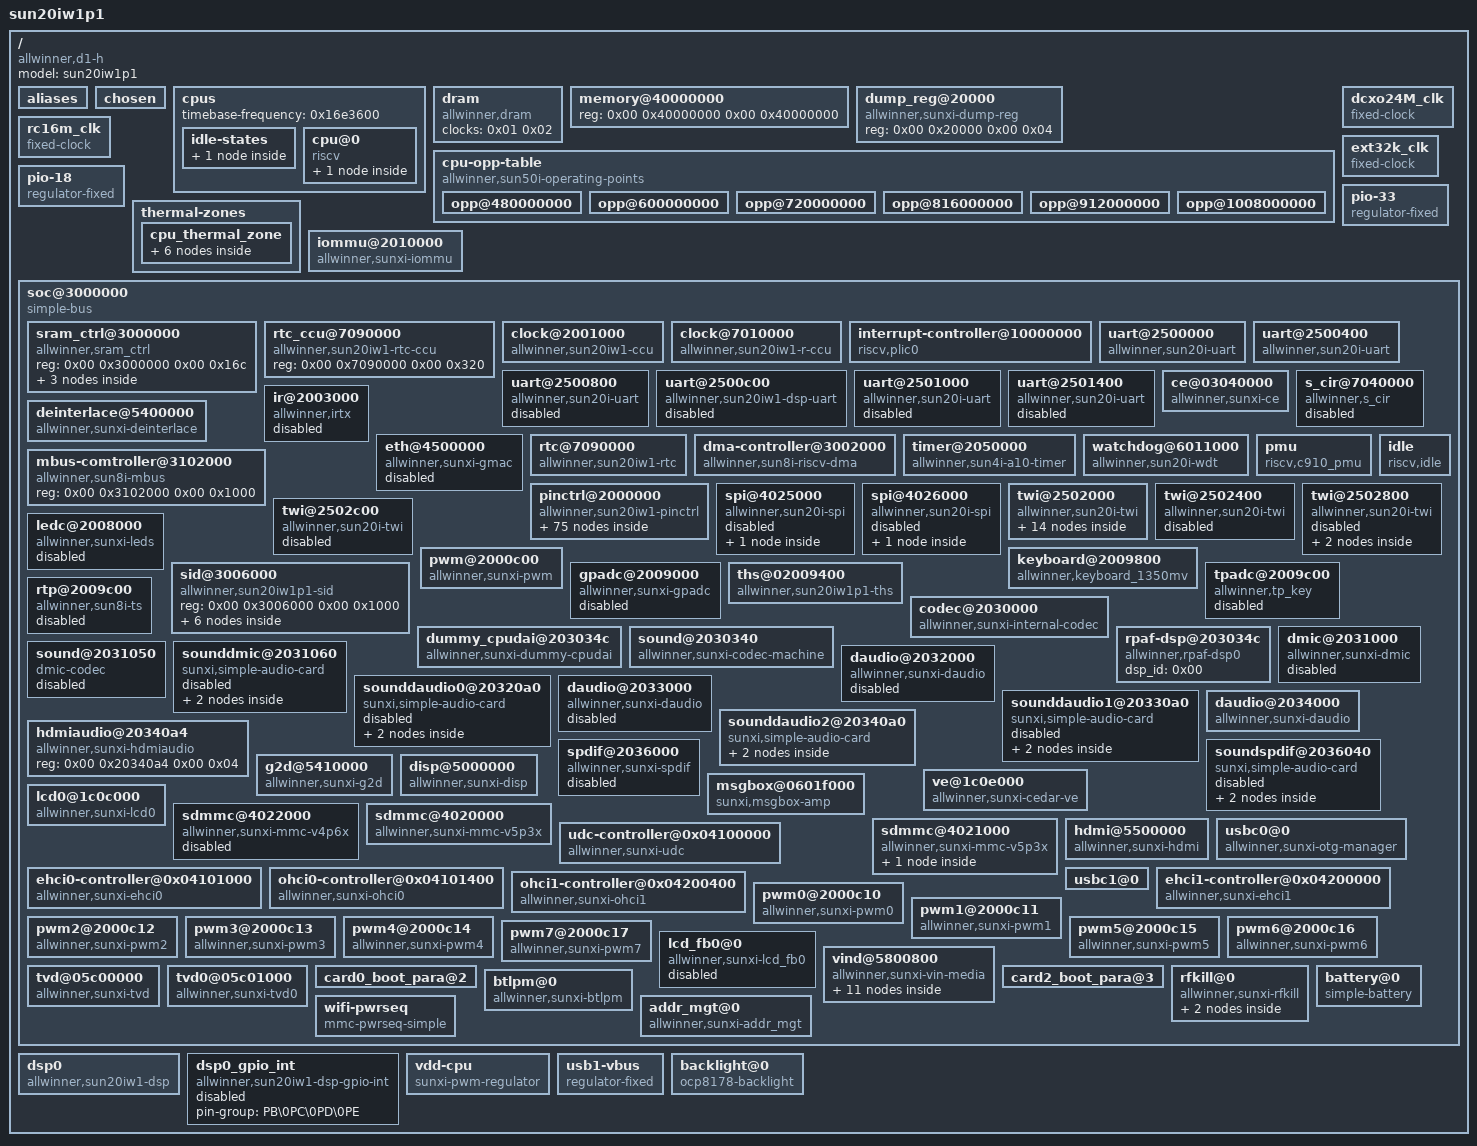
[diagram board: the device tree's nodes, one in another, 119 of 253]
/*
 * This is extracted from the supplied R-01 image's `/boot` partition.
 * TODO: work out what license this is covered by before committing.
 */
/dts-v1/;
 
/memreserve/	0x0000000042000000 0x0000000000100000;
/memreserve/	0x0000000041fc0000 0x0000000000020000;

/ {
	model = "sun20iw1p1";
	compatible = "allwinner,d1-h\0arm,sun20iw1p1\0allwinner,sun20iw1p1";
	#address-cells = <0x02>;
	#size-cells = <0x02>;
 
	aliases {
		serial0 = "/soc@3000000/uart@2500000";
		serial1 = "/soc@3000000/uart@2500400";
		serial2 = "/soc@3000000/uart@2500800";
		serial3 = "/soc@3000000/uart@2500c00";
		serial4 = "/soc@3000000/uart@2501000";
		serial5 = "/soc@3000000/uart@2501400";
		spi0 = "/soc@3000000/spi@4025000";
		spi1 = "/soc@3000000/spi@4026000";
		twi0 = "/soc@3000000/twi@2502000";
		twi1 = "/soc@3000000/twi@2502400";
		twi2 = "/soc@3000000/twi@2502800";
		twi3 = "/soc@3000000/twi@2502c00";
		mmc2 = "/soc@3000000/sdmmc@4022000";
		pwm0 = "/soc@3000000/pwm0@2000c10";
		pwm1 = "/soc@3000000/pwm1@2000c11";
		pwm2 = "/soc@3000000/pwm2@2000c12";
		pwm3 = "/soc@3000000/pwm3@2000c13";
		pwm4 = "/soc@3000000/pwm4@2000c14";
		pwm5 = "/soc@3000000/pwm5@2000c15";
		pwm6 = "/soc@3000000/pwm6@2000c16";
		pwm7 = "/soc@3000000/pwm7@2000c17";
		ir0 = "/soc@3000000/s_cir@7040000";
		ir1 = "/soc@3000000/ir@2003000";
		mmc0 = "/soc@3000000/sdmmc@4020000";
		ve0 = "/soc@3000000/ve@1c0e000";
		tvd = "/soc@3000000/tvd@05c00000";
		tvd0 = "/soc@3000000/tvd0@05c01000";
		dsp0 = "/dsp0";
		dsp0_gpio_int = "/dsp0_gpio_int";
		gmac0 = "/soc@3000000/eth@4500000";
	};
 
	chosen {
		bootargs = "console=ttyS0,115200n8 debug loglevel=7,initcall_debug=1 init=/init earlycon=sbi";
		stdout-path = "serial0:115200n8";
		linux,initrd-start = <0x42000000>;
		linux,initrd-end = <0x43000000>;
	};
 
	cpus {
		#address-cells = <0x01>;
		#size-cells = <0x00>;
		timebase-frequency = <0x16e3600>;
 
		idle-states {
 
			cpu-sleep {
				compatible = "riscv,idle-state";
				local-timer-stop;
				entry-latency-us = <0x3b>;
				exit-latency-us = <0x3b>;
				min-residency-us = <0x1388>;
				phandle = <0x03>;
			};
		};
 
		cpu@0 {
			device_type = "cpu";
			reg = <0x00>;
			status = "okay";
			compatible = "riscv";
			riscv,isa = "rv64imafdcvsu";
			mmu-type = "riscv,sv39";
			clocks = <0x01 0x87>;
			clock-frequency = <0x16e3600>;
			operating-points-v2 = <0x02>;
			cpu-idle-states = <0x03>;
			#cooling-cells = <0x02>;
			cpu-supply = <0x04>;
			phandle = <0x09>;
 
			interrupt-controller {
				#interrupt-cells = <0x01>;
				interrupt-controller;
				compatible = "riscv,cpu-intc";
				phandle = <0x0d>;
			};
		};
	};
 
	dram {
		device_type = "dram";
		compatible = "allwinner,dram";
		clocks = <0x01 0x02>;
		clock-names = "pll_ddr";
	};
 
	memory@40000000 {
		device_type = "memory";
		reg = <0x00 0x40000000 0x00 0x40000000>;
	};
 
	dump_reg@20000 {
		compatible = "allwinner,sunxi-dump-reg";
		reg = <0x00 0x20000 0x00 0x04>;
	};
 
	cpu-opp-table {
		compatible = "allwinner,sun50i-operating-points";
		nvmem-cells = <0x05 0x06>;
		nvmem-cell-names = "speed\0bin";
		opp-shared;
		phandle = <0x02>;
 
		opp@480000000 {
			opp-hz = <0x00 0x1c9c3800>;
			clock-latency-ns = <0x3b9b0>;
			opp-microvolt-a0 = <0xdbba0>;
			opp-microvolt-a1 = <0xdbba0>;
			opp-microvolt-b0 = <0xe7ef0>;
			opp-microvolt-b1 = <0xe7ef0>;
			opp-microvolt-c0 = <0xe7ef0>;
			opp-microvolt-c1 = <0xe7ef0>;
			opp-supported-hw = <0x07>;
		};
 
		opp@600000000 {
			opp-hz = <0x00 0x23c34600>;
			clock-latency-ns = <0x3b9b0>;
			opp-microvolt-b0 = <0xe7ef0>;
			opp-microvolt-c0 = <0xe7ef0>;
			opp-microvolt-c1 = <0xe7ef0>;
			opp-supported-hw = <0x06>;
		};
 
		opp@720000000 {
			opp-hz = <0x00 0x2aea5400>;
			clock-latency-ns = <0x3b9b0>;
			opp-microvolt-a0 = <0xe7ef0>;
			opp-microvolt-a1 = <0xdbba0>;
			opp-microvolt-b0 = <0xe7ef0>;
			opp-microvolt-b1 = <0xe7ef0>;
			opp-microvolt-c0 = <0xe7ef0>;
			opp-microvolt-c1 = <0xe7ef0>;
			opp-supported-hw = <0x07>;
		};
 
		opp@816000000 {
			opp-hz = <0x00 0x30a32c00>;
			clock-latency-ns = <0x3b9b0>;
			opp-microvolt-a0 = <0xf4240>;
			opp-microvolt-a1 = <0xdbba0>;
			opp-microvolt-b1 = <0xe7ef0>;
			opp-supported-hw = <0x01>;
		};
 
		opp@912000000 {
			opp-hz = <0x00 0x365c0400>;
			clock-latency-ns = <0x3b9b0>;
			opp-microvolt-a0 = <0x100590>;
			opp-microvolt-a1 = <0xdbba0>;
			opp-microvolt-b1 = <0xe7ef0>;
			opp-microvolt-c1 = <0xe7ef0>;
			opp-supported-hw = <0x05>;
		};
 
		opp@1008000000 {
			opp-hz = <0x00 0x3c14dc00>;
			clock-latency-ns = <0x3b9b0>;
			opp-microvolt-a0 = <0x10c8e0>;
			opp-microvolt-a1 = <0xe7ef0>;
			opp-microvolt-b1 = <0xe7ef0>;
			opp-microvolt-c1 = <0xe7ef0>;
			opp-supported-hw = <0x05>;
		};
	};
 
	dcxo24M_clk {
		#clock-cells = <0x00>;
		compatible = "fixed-clock";
		clock-frequency = <0x16e3600>;
		clock-output-names = "dcxo24M";
		phandle = <0x0b>;
	};
 
	rc16m_clk {
		#clock-cells = <0x00>;
		compatible = "fixed-clock";
		clock-frequency = <0xf42400>;
		clock-accuracy = <0x11e1a300>;
		clock-output-names = "rc-16m";
	};
 
	ext32k_clk {
		#clock-cells = <0x00>;
		compatible = "fixed-clock";
		clock-frequency = <0x8000>;
		clock-output-names = "ext-32k";
	};
 
	pio-18 {
		compatible = "regulator-fixed";
		regulator-name = "pio-18";
		regulator-min-microvolt = <0x1b7740>;
		regulator-max-microvolt = <0x1b7740>;
		phandle = <0x1e>;
	};
 
	pio-33 {
		compatible = "regulator-fixed";
		regulator-name = "pio-33";
		regulator-min-microvolt = <0x325aa0>;
		regulator-max-microvolt = <0x325aa0>;
		phandle = <0x1f>;
	};
 
	thermal-zones {
 
		cpu_thermal_zone {
			polling-delay-passive = <0x1f4>;
			polling-delay = <0x3e8>;
			thermal-sensors = <0x07 0x00>;
			sustainable-power = <0x4b0>;
 
			trips {
 
				trip-point@0 {
					temperature = <0x11170>;
					type = "passive";
					hysteresis = <0x00>;
				};
 
				trip-point@1 {
					temperature = <0x15f90>;
					type = "passive";
					hysteresis = <0x00>;
					phandle = <0x08>;
				};
 
				cpu_crit@0 {
					temperature = <0x1adb0>;
					type = "critical";
					hysteresis = <0x00>;
				};
			};
 
			cooling-maps {
 
				map0 {
					trip = <0x08>;
					cooling-device = <0x09 0xffffffff 0xffffffff>;
					contribution = <0x400>;
				};
			};
		};
	};
 
	iommu@2010000 {
		compatible = "allwinner,sunxi-iommu";
		reg = <0x00 0x2010000 0x00 0x1000>;
		interrupts-extended = <0x0a 0x50 0x04>;
		interrupt-names = "iommu-irq";
		clocks = <0x01 0x30>;
		clock-names = "iommu";
		#iommu-cells = <0x02>;
		status = "okay";
		phandle = <0x1a>;
	};
 
	soc@3000000 {
		#address-cells = <0x02>;
		#size-cells = <0x02>;
		compatible = "simple-bus";
		ranges;
 
		sram_ctrl@3000000 {
			compatible = "allwinner,sram_ctrl";
			reg = <0x00 0x3000000 0x00 0x16c>;
 
			soc_ver {
				offset = <0x24>;
				mask = <0x07>;
				shift = <0x00>;
				ver_a = <0x18590000>;
				ver_b = <0x18590002>;
				ver_d = <0x18590003>;
			};
 
			soc_id {
				offset = <0x200>;
				mask = <0x01>;
				shift = <0x16>;
			};
 
			soc_bin {
				offset = <0x00>;
				mask = <0x3ff>;
				shift = <0x00>;
			};
		};
 
		rtc_ccu@7090000 {
			compatible = "allwinner,sun20iw1-rtc-ccu";
			device_type = "rtc-ccu";
			reg = <0x00 0x7090000 0x00 0x320>;
			#clock-cells = <0x01>;
			phandle = <0x0c>;
		};
 
		clock@2001000 {
			compatible = "allwinner,sun20iw1-ccu";
			reg = <0x00 0x2001000 0x00 0x1000>;
			clocks = <0x0b 0x0c 0x03 0x0c 0x00>;
			clock-names = "hosc\0losc\0iosc";
			#clock-cells = <0x01>;
			#reset-cells = <0x01>;
			phandle = <0x01>;
		};
 
		clock@7010000 {
			compatible = "allwinner,sun20iw1-r-ccu";
			reg = <0x00 0x7010000 0x00 0x240>;
			clocks = <0x0b 0x0c 0x03 0x0c 0x00 0x01 0x04>;
			clock-names = "hosc\0losc\0iosc\0pll-periph0";
			#clock-cells = <0x01>;
			#reset-cells = <0x01>;
			phandle = <0x15>;
		};
 
		interrupt-controller@10000000 {
			compatible = "riscv,plic0";
			#address-cells = <0x02>;
			#interrupt-cells = <0x02>;
			interrupt-controller;
			reg = <0x00 0x10000000 0x00 0x4000000>;
			interrupts-extended = <0x0d 0xffffffff 0x0d 0x09>;
			reg-names = "control";
			riscv,max-priority = <0x07>;
			riscv,ndev = <0xc8>;
			phandle = <0x0a>;
		};
 
		uart@2500000 {
			compatible = "allwinner,sun20i-uart";
			device_type = "uart0";
			reg = <0x00 0x2500000 0x00 0x400>;
			interrupts-extended = <0x0a 0x12 0x04>;
			clocks = <0x01 0x3f>;
			clock-names = "uart0";
			resets = <0x01 0x12>;
			sunxi,uart-fifosize = <0x40>;
			uart0_port = <0x00>;
			uart0_type = <0x02>;
			status = "okay";
			pinctrl-names = "default\0sleep";
			pinctrl-0 = <0x0e>;
			pinctrl-1 = <0x0f>;
		};
 
		uart@2500400 {
			compatible = "allwinner,sun20i-uart";
			device_type = "uart1";
			reg = <0x00 0x2500400 0x00 0x400>;
			interrupts-extended = <0x0a 0x13 0x04>;
			sunxi,uart-fifosize = <0x100>;
			clocks = <0x01 0x40>;
			clock-names = "uart1";
			resets = <0x01 0x13>;
			uart1_port = <0x01>;
			uart1_type = <0x04>;
			status = "okay";
			pinctrl-names = "default\0sleep";
			pinctrl-0 = <0x10>;
			pinctrl-1 = <0x11>;
		};
 
		uart@2500800 {
			compatible = "allwinner,sun20i-uart";
			device_type = "uart2";
			reg = <0x00 0x2500800 0x00 0x400>;
			interrupts-extended = <0x0a 0x14 0x04>;
			sunxi,uart-fifosize = <0x100>;
			clocks = <0x01 0x41>;
			clock-names = "uart2";
			resets = <0x01 0x14>;
			uart2_port = <0x02>;
			uart2_type = <0x04>;
			status = "disabled";
			pinctrl-names = "default\0sleep";
			pinctrl-0 = <0x12>;
			pinctrl-1 = <0x13>;
		};
 
		uart@2500c00 {
			compatible = "allwinner,sun20iw1-dsp-uart";
			device_type = "uart3";
			reg = <0x00 0x2500c00 0x00 0x400>;
			interrupts-extended = <0x0a 0x15 0x04>;
			sunxi,uart-fifosize = <0x100>;
			clocks = <0x01 0x42>;
			clock-names = "uart3";
			resets = <0x01 0x15>;
			uart3_port = <0x03>;
			uart3_type = <0x04>;
			status = "disabled";
			pinctrl-names = "default\0sleep";
			pinctrl-0 = <0x14>;
			pinctrl-1 = <0x14>;
		};
 
		uart@2501000 {
			compatible = "allwinner,sun20i-uart";
			device_type = "uart4";
			reg = <0x00 0x2501000 0x00 0x400>;
			interrupts-extended = <0x0a 0x16 0x04>;
			sunxi,uart-fifosize = <0x100>;
			clocks = <0x01 0x43>;
			clock-names = "uart4";
			resets = <0x01 0x16>;
			uart4_port = <0x04>;
			uart4_type = <0x02>;
			status = "disabled";
		};
 
		uart@2501400 {
			compatible = "allwinner,sun20i-uart";
			device_type = "uart5";
			reg = <0x00 0x2501400 0x00 0x400>;
			interrupts-extended = <0x0a 0x17 0x04>;
			sunxi,uart-fifosize = <0x100>;
			clocks = <0x01 0x44>;
			clock-names = "uart5";
			resets = <0x01 0x17>;
			uart5_port = <0x05>;
			uart5_type = <0x02>;
			status = "disabled";
		};
 
		ce@03040000 {
			compatible = "allwinner,sunxi-ce";
			device_name = "ce";
			reg = <0x00 0x3040000 0x00 0xa0 0x00 0x3040800 0x00 0xa0>;
			interrupts-extended = <0x0a 0x44 0x01 0x0a 0x45 0x01>;
			clock-frequency = <0x17d78400>;
			clocks = <0x01 0x24 0x01 0x23 0x01 0x34 0x01 0x05>;
			clock-names = "bus_ce\0ce_clk\0mbus_ce\0pll_periph0_2x";
			resets = <0x01 0x04>;
			status = "okay";
		};
 
		s_cir@7040000 {
			compatible = "allwinner,s_cir";
			reg = <0x00 0x7040000 0x00 0x400>;
			interrupts-extended = <0x0a 0xa7 0x04>;
			clocks = <0x15 0x06 0x0b 0x15 0x05>;
			clock-names = "bus\0pclk\0mclk";
			resets = <0x15 0x03>;
			supply = [00];
			supply_vol = [00];
			status = "disabled";
			pinctrl-names = "default\0sleep";
			pinctrl-0 = <0x16>;
			pinctrl-1 = <0x17>;
		};
 
		ir@2003000 {
			compatible = "allwinner,irtx";
			reg = <0x00 0x2003000 0x00 0x400>;
			interrupts-extended = <0x0a 0x23 0x04>;
			clocks = <0x01 0x52 0x0b 0x01 0x51>;
			clock-names = "bus\0pclk\0mclk";
			resets = <0x01 0x21>;
			status = "disabled";
			pinctrl-names = "default\0sleep";
			pinctrl-0 = <0x18>;
			pinctrl-1 = <0x19>;
		};
 
		deinterlace@5400000 {
			compatible = "allwinner,sunxi-deinterlace";
			reg = <0x00 0x5400000 0x00 0xffff>;
			interrupts-extended = <0x0a 0x68 0x04>;
			clocks = <0x01 0x1f 0x01 0x20 0x01 0x05>;
			clock-names = "clk_di\0pll_periph\0clk_bus_di";
			resets = <0x01 0x02>;
			reset-names = "rst_bus_di";
			assigned-clocks = <0x01 0x1f>;
			assigned-clock-parents = <0x01 0x05>;
			assigned-clock-rates = <0x11e1a300>;
			iommus = <0x1a 0x04 0x01>;
			status = "okay";
		};
 
		eth@4500000 {
			compatible = "allwinner,sunxi-gmac";
			reg = <0x00 0x4500000 0x00 0x10000 0x00 0x3000030 0x00 0x04>;
			interrupts-extended = <0x0a 0x3e 0x04>;
			interrupt-names = "gmacirq";
			clocks = <0x01 0x50 0x01 0x4f>;
			clock-names = "gmac\0ephy";
			resets = <0x01 0x20>;
			device_type = "gmac0";
			pinctrl-0 = <0x1b>;
			pinctrl-1 = <0x1c>;
			pinctrl-names = "default\0sleep";
			phy-mode = "rgmii";
			use_ephy25m = <0x01>;
			tx-delay = <0x03>;
			rx-delay = <0x00>;
			phy-rst = <0x1d 0x04 0x10 0x00>;
			gmac-power0;
			gmac-power1;
			gmac-power2;
			status = "disabled";
		};
 
		rtc@7090000 {
			compatible = "allwinner,sun20iw1-rtc";
			device_type = "rtc";
			wakeup-source;
			interrupts-extended = <0x0a 0xa0 0x04>;
			reg = <0x00 0x7090000 0x00 0x320>;
			clocks = <0x15 0x07 0x0c 0x08 0x0c 0x06>;
			clock-names = "r-ahb-rtc\0rtc-spi\0rtc-1k";
			resets = <0x15 0x04>;
			gpr_cur_pos = <0x06>;
			phandle = <0x69>;
		};
 
		dma-controller@3002000 {
			compatible = "allwinner,sun8i-riscv-dma";
			reg = <0x00 0x3002000 0x00 0x1000>;
			interrupts-extended = <0x0a 0x42 0x04>;
			clocks = <0x01 0x27 0x01 0x32>;
			clock-names = "bus\0mbus";
			resets = <0x01 0x06>;
			dma-channels = <0x08>;
			dma-requests = <0x30>;
			#dma-cells = <0x01>;
			status = "okay";
			phandle = <0x20>;
		};
 
		timer@2050000 {
			compatible = "allwinner,sun4i-a10-timer";
			device_type = "soc_timer";
			reg = <0x00 0x2050000 0x00 0xa0>;
			interrupts-extended = <0x0a 0x4b 0x04>;
			clocks = <0x0b>;
			status = "okay";
		};
 
		watchdog@6011000 {
			compatible = "allwinner,sun20i-wdt";
			reg = <0x00 0x6011000 0x00 0x20>;
			interrupts-extended = <0x0a 0x93 0x04>;
		};
 
		mbus-comtroller@3102000 {
			compatible = "allwinner,sun8i-mbus";
			reg = <0x00 0x3102000 0x00 0x1000>;
			#mbus-cells = <0x01>;
		};
 
		pmu {
			compatible = "riscv,c910_pmu";
		};
 
		idle {
			compatible = "riscv,idle";
		};
 
		pinctrl@2000000 {
			compatible = "allwinner,sun20iw1-pinctrl";
			reg = <0x00 0x2000000 0x00 0x500>;
			interrupts-extended = <0x0a 0x55 0x04 0x0a 0x57 0x04 0x0a 0x59 0x04 0x0a 0x5b 0x04 0x0a 0x5d 0x04 0x0a 0x5f 0x04>;
			device_type = "pio";
			clocks = <0x01 0x1a 0x0b 0x0c 0x03>;
			clock-names = "apb\0hosc\0losc";
			gpio-controller;
			#gpio-cells = <0x03>;
			interrupt-controller;
			#interrupt-cells = <0x03>;
			#size-cells = <0x00>;
			vcc-pf-supply = <0x1e>;
			vcc-pfo-supply = <0x1f>;
			phandle = <0x1d>;
 
			test_pins@0 {
				allwinner,pins = "PB0\0PB1";
				allwinner,function = "test";
				allwinner,muxsel = <0x07>;
				allwinner,drive = <0x01>;
				allwinner,pull = <0x01>;
			};
 
			test_pins@1 {
				pins = "PB0\0PB1";
				function = "io_disabled";
				allwinner,muxsel = <0x0f>;
				allwinner,drive = <0x01>;
				allwinner,pull = <0x01>;
			};
 
			gmac@0 {
				pins = "PE0\0PE1\0PE2\0PE3\0PE4\0PE5\0PE6\0PE7\0PE8\0PE9\0PE10\0PE11\0PE12\0PE13\0PE14\0PE15";
				function = "gmac0";
				drive-strength = <0x0a>;
				muxsel = <0x08>;
				phandle = <0x1b>;
			};
 
			gmac@1 {
				pins = "PE0\0PE1\0PE2\0PE3\0PE4\0PE5\0PE6\0PE7\0PE8\0PE9\0PE10\0PE11\0PE12\0PE13\0PE14\0PE15";
				function = "gpio_in";
				drive-strength = <0x0a>;
				phandle = <0x1c>;
			};
 
			ir1@0 {
				pins = "PB0";
				function = "ir";
				drive-strength = <0x0a>;
				bias-pull-up;
				phandle = <0x18>;
			};
 
			csi_mclk0@0 {
				pins = "PE3";
				function = "csi0";
				drive-strength = <0x0a>;
				phandle = <0x62>;
			};
 
			csi_mclk0@1 {
				pins = "PE3";
				function = "gpio_in";
				phandle = <0x63>;
			};
 
			csi0@0 {
				pins = "PE2\0PE0\0PE1\0PE4\0PE5\0PE6\0PE7\0PE8\0PE9\0PE10\0PE11";
				function = "ncsi0";
				drive-strength = <0x0a>;
				phandle = <0x64>;
			};
 
			csi0@1 {
				pins = "PE2\0PE0\0PE1\0PE4\0PE5\0PE6\0PE7\0PE8\0PE9\0PE10\0PE11";
				function = "io_disabled";
				drive-strength = <0x0a>;
				phandle = <0x65>;
			};
 
			lvds0@0 {
				pins = "PD0\0PD1\0PD2\0PD3\0PD4\0PD5\0PD6\0PD7\0PD8\0PD9";
				function = "lvds0";
				drive-strength = <0x1e>;
				bias-disable;
			};
 
			lvds0@1 {
				pins = "PD0\0PD1\0PD2\0PD3\0PD4\0PD5\0PD6\0PD7\0PD8\0PD9";
				function = "io_disabled";
				drive-strength = <0x1e>;
				bias-disable;
			};
 
			rgb24@0 {
				pins = "PB2\0PB3\0PD0\0PD1\0PD2\0PD3\0PD4\0PD5\0PB4\0PB5\0PD6\0PD7\0PD8\0PD9\0PD10\0PD11\0PB6\0PB7\0PD12\0PD13\0PD14\0PD15\0PD16\0PD17\0PD18\0PD19\0PD20\0PD21";
				function = "lcd0";
				drive-strength = <0x1e>;
				bias-disable;
			};
 
			rgb24@1 {
				pins = "PB2\0PB3\0PD0\0PD1\0PD2\0PD3\0PD4\0PD5\0PB4\0PB5\0PD6\0PD7\0PD8\0PD9\0PD10\0PD11\0PB6\0PB7\0PD12\0PD13\0PD14\0PD15\0PD16\0PD17\0PD18\0PD19\0PD20\0PD21";
				function = "io_disabled";
				bias-disable;
			};
 
			rgb18@0 {
				pins = "PD0\0PD1\0PD2\0PD3\0PD4\0PD5\0PD6\0PD7\0PD8\0PD9\0PD10\0PD11\0PD12\0PD13\0PD14\0PD15\0PD16\0PD17\0PD18\0PD19\0PD20\0PD21";
				function = "lcd0";
				drive-strength = <0x1e>;
				bias-disable;
			};
 
			rgb18@1 {
				pins = "PD0\0PD1\0PD2\0PD3\0PD4\0PD5\0PD6\0PD7\0PD8\0PD9\0PD10\0PD11\0PD12\0PD13\0PD14\0PD15\0PD16\0PD17\0PD18\0PD19\0PD20\0PD21";
				function = "io_disabled";
				bias-disable;
			};
 
			dsi2lane@0 {
				pins = "PD0\0PD1\0PD2\0PD3\0PD4\0PD5";
				function = "dsi";
				drive-strength = <0x1e>;
				bias-disable;
			};
 
			dsi2lane@1 {
				pins = "PD0\0PD1\0PD2\0PD3\0PD4\0PD5";
				function = "io_disabled";
				bias-disable;
			};
 
			dsi4lane@0 {
				pins = "PD0\0PD1\0PD2\0PD3\0PD4\0PD5\0PD6\0PD7\0PD8\0PD9";
				function = "dsi";
				drive-strength = <0x1e>;
				bias-disable;
				phandle = <0x4f>;
			};
 
			dsi4lane@1 {
				pins = "PD0\0PD1\0PD2\0PD3\0PD4\0PD5\0PD6\0PD7\0PD8\0PD9";
				function = "io_disabled";
				bias-disable;
				phandle = <0x50>;
			};
 
			sdc0@0 {
				allwinner,pins = "PF0\0PF1\0PF2\0PF3\0PF4\0PF5";
				allwinner,function = "sdc0";
				allwinner,muxsel = <0x02>;
				allwinner,drive = <0x03>;
				allwinner,pull = <0x01>;
				pins = "PF0\0PF1\0PF2\0PF3\0PF4\0PF5";
				function = "sdc0";
				drive-strength = <0x1e>;
				bias-pull-up;
				power-source = <0xce4>;
				phandle = <0x53>;
			};
 
			sdc0@1 {
				pins = "PF0\0PF1\0PF2\0PF3\0PF4\0PF5";
				function = "sdc0";
				drive-strength = <0x1e>;
				bias-pull-up;
				power-source = <0x708>;
				phandle = <0x54>;
			};
 
			sdc0@2 {
				pins = "PF0\0PF1\0PF2\0PF3\0PF4\0PF5";
				function = "gpio_in";
				phandle = <0x55>;
			};
 
			sdc0@3 {
				pins = "PF2\0PF4";
				function = "uart0";
				drive-strength = <0x0a>;
				bias-pull-up;
				phandle = <0x56>;
			};
 
			sdc0@4 {
				pins = "PF0\0PF1\0PF3\0PF5";
				function = "jtag";
				drive-strength = <0x0a>;
				bias-pull-up;
				phandle = <0x57>;
			};
 
			sdc1@0 {
				pins = "PG0\0PG1\0PG2\0PG3\0PG4\0PG5";
				function = "sdc1";
				drive-strength = <0x1e>;
				bias-pull-up;
				phandle = <0x58>;
			};
 
			sdc1@1 {
				pins = "PG0\0PG1\0PG2\0PG3\0PG4\0PG5";
				function = "gpio_in";
				phandle = <0x59>;
			};
 
			sdc2@0 {
				allwinner,pins = "PC2\0PC3\0PC4\0PC5\0PC6\0PC7";
				allwinner,function = "sdc2";
				allwinner,muxsel = <0x03>;
				allwinner,drive = <0x03>;
				allwinner,pull = <0x01>;
				pins = "PC2\0PC3\0PC4\0PC5\0PC6\0PC7";
				function = "sdc2";
				drive-strength = <0x1e>;
				bias-pull-up;
				phandle = <0x51>;
			};
 
			sdc2@1 {
				pins = "PC2\0PC3\0PC4\0PC5\0PC6\0PC7";
				function = "gpio_in";
				phandle = <0x52>;
			};
 
			uart0_pins@0 {
				pins = "PB8\0PB9";
				function = "uart0";
				drive-strength = <0x0a>;
				bias-pull-up;
				phandle = <0x0e>;
			};
 
			uart0_pins@1 {
				pins = "PB8\0PB9";
				function = "gpio_in";
				phandle = <0x0f>;
			};
 
			uart1_pins@0 {
				pins = "PG6\0PG7\0PG8\0PG9";
				function = "uart1";
				drive-strength = <0x0a>;
				bias-pull-up;
				phandle = <0x10>;
			};
 
			uart1_pins {
				pins = "PG6\0PG7\0PG8\0PG9";
				function = "gpio_in";
				phandle = <0x11>;
			};
 
			uart2_pins@0 {
				pins = "PC0\0PC1";
				function = "uart2";
				drive-strength = <0x0a>;
				bias-pull-up;
				phandle = <0x12>;
			};
 
			uart2_pins@1 {
				pins = "PC0\0PC1";
				function = "gpio_in";
				phandle = <0x13>;
			};
 
			uart3_pins@0 {
				pins = "PD10\0PD11";
				function = "uart3";
				muxsel = <0x05>;
				drive-strength = <0x0a>;
				bias-pull-up;
				phandle = <0x14>;
			};
 
			twi0@0 {
				pins = "PB10\0PB11";
				function = "twi0";
				drive-strength = <0x0a>;
				phandle = <0x26>;
			};
 
			twi0@1 {
				pins = "PB10\0PB11";
				function = "gpio_in";
				phandle = <0x27>;
			};
 
			twi1@0 {
				pins = "PB4\0PB5";
				function = "twi1";
				drive-strength = <0x0a>;
				phandle = <0x29>;
			};
 
			twi1@1 {
				pins = "PB4\0PB5";
				function = "gpio_in";
				phandle = <0x2a>;
			};
 
			twi2@0 {
				pins = "PB0\0PB1";
				function = "twi2";
				drive-strength = <0x0a>;
				phandle = <0x2b>;
			};
 
			twi2@1 {
				pins = "PB0\0PB1";
				function = "gpio_in";
				phandle = <0x2c>;
			};
 
			twi3@0 {
				pins = "PB6\0PB7";
				function = "twi3";
				drive-strength = <0x0a>;
				phandle = <0x2d>;
			};
 
			twi3@1 {
				pins = "PB6\0PB7";
				function = "gpio_in";
				phandle = <0x2e>;
			};
 
			dmic@0 {
				pins = "PE17\0PB11\0PB10\0PD17";
				function = "dmic";
				drive-strength = <0x14>;
				bias-disable;
				phandle = <0x3c>;
			};
 
			dmic@1 {
				pins = "PE17\0PB11\0PB10\0PD17";
				function = "io_disabled";
				drive-strength = <0x14>;
				bias-disable;
				phandle = <0x3d>;
			};
 
			daudio0@0 {
				pins = "PE17\0PE16\0PE15";
				function = "i2s0";
				drive-strength = <0x14>;
				bias-disable;
				phandle = <0x40>;
			};
 
			daudio0@1 {
				pins = "PE14";
				function = "i2s0_din";
				drive-strength = <0x14>;
				bias-disable;
				phandle = <0x41>;
			};
 
			daudio0@2 {
				pins = "PE13";
				function = "i2s0_dout";
				drive-strength = <0x14>;
				bias-disable;
				phandle = <0x42>;
			};
 
			daudio0_sleep@0 {
				pins = "PE17\0PE16\0PE15\0PE14\0PE13";
				function = "io_disabled";
				drive-strength = <0x14>;
				bias-disable;
				phandle = <0x43>;
			};
 
			daudio1@0 {
				pins = "PG11\0PG12\0PG13";
				function = "i2s1";
				drive-strength = <0x14>;
				bias-disable;
				phandle = <0x45>;
			};
 
			daudio1@1 {
				pins = "PG14";
				function = "i2s1_din";
				drive-strength = <0x14>;
				bias-disable;
				phandle = <0x46>;
			};
 
			daudio1@2 {
				pins = "PG15";
				function = "i2s1_dout";
				drive-strength = <0x14>;
				bias-disable;
				phandle = <0x47>;
			};
 
			daudio1_sleep@0 {
				pins = "PG11\0PG12\0PG13\0PG14\0PG15";
				function = "io_disabled";
				drive-strength = <0x14>;
				bias-disable;
				phandle = <0x48>;
			};
 
			daudio2@0 {
				pins = "PB7\0PB5\0PB6";
				function = "i2s2";
				drive-strength = <0x14>;
				bias-disable;
			};
 
			daudio2@1 {
				pins = "PB4";
				function = "i2s2_dout";
				drive-strength = <0x14>;
				bias-disable;
			};
 
			daudio2@2 {
				pins = "PB3";
				function = "i2s2_din";
				drive-strength = <0x14>;
				bias-disable;
			};
 
			daudio2_sleep@0 {
				pins = "PB7\0PB5\0PB6\0PB4\0PB3";
				function = "io_disabled";
				drive-strength = <0x14>;
				bias-disable;
			};
 
			spdif@0 {
				pins = "PB0";
				function = "spdif";
				drive-strength = <0x14>;
				bias-disable;
				phandle = <0x4c>;
			};
 
			spdif_sleep@0 {
				pins = "PB0";
				function = "io_disabled";
				drive-strength = <0x14>;
				bias-disable;
				phandle = <0x4d>;
			};
 
			spi0@0 {
				pins = "PC2\0PC4\0PC5";
				function = "spi0";
				muxsel = <0x02>;
				drive-strength = <0x0a>;
				phandle = <0x21>;
			};
 
			spi0@1 {
				pins = "PC3\0PC7\0PC6";
				function = "spi0";
				muxsel = <0x02>;
				drive-strength = <0x0a>;
				bias-pull-up;
				phandle = <0x22>;
			};
 
			spi0@2 {
				pins = "PC2\0PC3\0PC4\0PC5\0PC6\0PC7";
				function = "gpio_in";
				muxsel = <0x00>;
				drive-strength = <0x0a>;
				phandle = <0x23>;
			};
 
			spi1@0 {
				pins = "PD11\0PD12\0PD13";
				function = "spi1";
				drive-strength = <0x0a>;
				phandle = <0x24>;
			};
 
			spi1@1 {
				pins = "PD10";
				function = "spi1";
				drive-strength = <0x0a>;
				bias-pull-up;
			};
 
			spi1@2 {
				pins = "PD11\0PD12";
				function = "gpio_in";
				drive-strength = <0x0a>;
				phandle = <0x25>;
			};
 
			ledc@0 {
				pins = "PC0";
				function = "ledc";
				drive-strength = <0x0a>;
				phandle = <0x2f>;
			};
 
			ledc@1 {
				pins = "PC0";
				function = "gpio_in";
				phandle = <0x30>;
			};
 
			pwm0@0 {
				pins = "PD16";
				function = "pwm0";
				drive-strength = <0x0a>;
				bias-pull-up;
				phandle = <0x5e>;
			};
 
			pwm0@1 {
				pins = "PD16";
				function = "gpio_in";
				bias-disable;
				phandle = <0x5f>;
			};
 
			pwm2@0 {
				pins = "PD18";
				function = "pwm2";
				drive-strength = <0x0a>;
				bias-pull-up;
				phandle = <0x60>;
			};
 
			pwm2@1 {
				pins = "PD18";
				function = "gpio_out";
				phandle = <0x61>;
			};
 
			s_cir@0 {
				pins = "PB12";
				function = "ir";
				drive-strength = <0x0a>;
				bias-pull-up;
				phandle = <0x16>;
			};
 
			s_cir@1 {
				pins = "PB12";
				function = "gpio_in";
				phandle = <0x17>;
			};
 
			ir1@1 {
				pins = "PB0";
				function = "gpio_in";
				phandle = <0x19>;
			};
 
			backlight_control@0 {
				pins = "PD20";
				function = "gpio_out";
			};
		};
 
		spi@4025000 {
			#address-cells = <0x01>;
			#size-cells = <0x00>;
			compatible = "allwinner,sun20i-spi";
			device_type = "spi0";
			reg = <0x00 0x4025000 0x00 0x300>;
			interrupts-extended = <0x0a 0x1f 0x04>;
			clocks = <0x01 0x04 0x01 0x4b 0x01 0x4d>;
			clock-names = "pll\0mod\0bus";
			resets = <0x01 0x1e>;
			clock-frequency = <0x5f5e100>;
			pinctrl-names = "default\0sleep";
			spi0_cs_number = <0x01>;
			spi0_cs_bitmap = <0x01>;
			dmas = <0x20 0x16 0x20 0x16>;
			dma-names = "tx\0rx";
			status = "disabled";
			pinctrl-0 = <0x21 0x22>;
			pinctrl-1 = <0x23>;
			spi_slave_mode = <0x00>;
 
			spi-nand@0 {
				compatible = "spi-nand";
				spi-max-frequency = <0x5f5e100>;
				reg = <0x00>;
				spi-rx-bus-width = <0x04>;
				spi-tx-bus-width = <0x04>;
				status = "disabled";
			};
		};
 
		spi@4026000 {
			#address-cells = <0x01>;
			#size-cells = <0x00>;
			compatible = "allwinner,sun20i-spi";
			reg = <0x00 0x4026000 0x00 0x1000>;
			interrupts-extended = <0x0a 0x20 0x04>;
			clocks = <0x01 0x04 0x01 0x4c 0x01 0x4e>;
			clock-names = "pll\0mod\0bus";
			resets = <0x01 0x1f>;
			clock-frequency = <0x5f5e100>;
			spi1_cs_number = <0x01>;
			spi1_cs_bitmap = <0x01>;
			dmas = <0x20 0x17 0x20 0x17>;
			dma-names = "tx\0rx";
			status = "disabled";
			pinctrl-0 = <0x24>;
			pinctrl-1 = <0x25>;
			pinctrl-names = "default\0sleep";
			spi_slave_mode = <0x00>;
			spi_dbi_enable = <0x01>;
 
			spi_board1@0 {
				device_type = "spi-dbi";
				compatible = "sunxi,spidbi";
				spi-max-frequency = <0x5f5e100>;
				reg = <0x00>;
				spi-rx-bus-width = <0x04>;
				spi-tx-bus-width = <0x04>;
				status = "okay";
			};
		};
 
		twi@2502000 {
			#address-cells = <0x01>;
			#size-cells = <0x00>;
			compatible = "allwinner,sun20i-twi";
			device_type = "twi0";
			reg = <0x00 0x2502000 0x00 0x400>;
			interrupts-extended = <0x0a 0x19 0x04>;
			clocks = <0x01 0x45>;
			resets = <0x01 0x18>;
			clock-names = "bus";
			clock-frequency = <0x61a80>;
			dmas = <0x20 0x2b 0x20 0x2b>;
			dma-names = "tx\0rx";
			status = "okay";
			pinctrl-0 = <0x26>;
			pinctrl-1 = <0x27>;
			pinctrl-names = "default\0sleep";
 
			pmic@34 {
				interrupt-controller;
				#interrupt-cells = <0x01>;
				compatible = "x-powers,axp221";
				reg = <0x34>;
				interrupt-parent = <0x1d>;
				interrupts = <0x04 0x09 0x08>;
 
				regulators {
					x-powers,dcdc-freq = <0xbb8>;
 
					aldo1 {
						regulator-always-on;
						regulator-min-microvolt = <0x325aa0>;
						regulator-max-microvolt = <0x325aa0>;
						regulator-name = "audio-vdd";
					};
 
					aldo2 {
						regulator-always-on;
						regulator-min-microvolt = <0x325aa0>;
						regulator-max-microvolt = <0x325aa0>;
						regulator-name = "display-vcc";
					};
 
					aldo3 {
						regulator-always-on;
						regulator-min-microvolt = <0x1b7740>;
						regulator-max-microvolt = <0x1b7740>;
						regulator-name = "wifi-vdd";
						phandle = <0x5b>;
					};
 
					dldo1 {
						regulator-always-on;
						regulator-min-microvolt = <0x325aa0>;
						regulator-max-microvolt = <0x325aa0>;
						regulator-name = "wifi-vcc1";
						phandle = <0x5a>;
					};
 
					dldo2 {
						regulator-always-on;
						regulator-min-microvolt = <0x325aa0>;
						regulator-max-microvolt = <0x325aa0>;
						regulator-name = "dldo2";
					};
 
					dldo3 {
						regulator-always-on;
						regulator-min-microvolt = <0x325aa0>;
						regulator-max-microvolt = <0x325aa0>;
						regulator-name = "dldo3";
					};
 
					dldo4 {
						regulator-always-on;
						regulator-min-microvolt = <0x325aa0>;
						regulator-max-microvolt = <0x325aa0>;
						regulator-name = "dldo4";
					};
 
					eldo1 {
						regulator-always-on;
						regulator-min-microvolt = <0x325aa0>;
						regulator-max-microvolt = <0x325aa0>;
						regulator-name = "wifi-vcc2";
					};
 
					eldo2 {
						regulator-always-on;
						regulator-min-microvolt = <0x325aa0>;
						regulator-max-microvolt = <0x325aa0>;
						regulator-name = "wifi-vcc3";
					};
 
					eldo3 {
						regulator-always-on;
						regulator-min-microvolt = <0x325aa0>;
						regulator-max-microvolt = <0x325aa0>;
						regulator-name = "wifi-vcc4";
					};
				};
 
				battery-power-supply {
					compatible = "x-powers,axp221-battery-power-supply";
					monitored-battery = <0x28>;
				};
 
				ac_power_supply {
					compatible = "x-powers,axp221-ac-power-supply";
				};
			};
		};
 
		twi@2502400 {
			#address-cells = <0x01>;
			#size-cells = <0x00>;
			compatible = "allwinner,sun20i-twi";
			device_type = "twi1";
			reg = <0x00 0x2502400 0x00 0x400>;
			interrupts-extended = <0x0a 0x1a 0x04>;
			clocks = <0x01 0x46>;
			resets = <0x01 0x19>;
			clock-names = "bus";
			clock-frequency = <0x61a80>;
			dmas = <0x20 0x2c 0x20 0x2c>;
			dma-names = "tx\0rx";
			status = "disabled";
			pinctrl-0 = <0x29>;
			pinctrl-1 = <0x2a>;
			pinctrl-names = "default\0sleep";
		};
 
		twi@2502800 {
			#address-cells = <0x01>;
			#size-cells = <0x00>;
			compatible = "allwinner,sun20i-twi";
			device_type = "twi2";
			reg = <0x00 0x2502800 0x00 0x400>;
			interrupts-extended = <0x0a 0x1b 0x04>;
			clocks = <0x01 0x47>;
			resets = <0x01 0x1a>;
			clock-names = "bus";
			clock-frequency = <0x61a80>;
			dmas = <0x20 0x2d 0x20 0x2d>;
			dma-names = "tx\0rx";
			status = "disabled";
			pinctrl-0 = <0x2b>;
			pinctrl-1 = <0x2c>;
			pinctrl-names = "default\0sleep";
 
			gpio@38 {
				compatible = "nxp,pcf8574";
				reg = <0x38>;
				gpio_base = <0x7e4>;
				gpio-controller;
				#gpio-cells = <0x02>;
				interrupt-controller;
				#interrupt-cells = <0x02>;
				interrupt-parent = <0x1d>;
				interrupts = <0x01 0x02 0x02>;
				status = "okay";
			};
 
			ctp@14 {
				compatible = "allwinner,goodix";
				device_type = "ctp";
				reg = <0x14>;
				status = "disabled";
				ctp_name = "gt9xxnew_ts";
				ctp_twi_id = <0x02>;
				ctp_twi_addr = <0x14>;
				ctp_screen_max_x = <0x320>;
				ctp_screen_max_y = <0x500>;
				ctp_revert_x_flag = <0x00>;
				ctp_revert_y_flag = <0x01>;
				ctp_exchange_x_y_flag = <0x00>;
				ctp_int_port = <0x1d 0x06 0x0e 0x00>;
				ctp_wakeup = <0x1d 0x06 0x0f 0x00>;
			};
		};
 
		twi@2502c00 {
			#address-cells = <0x01>;
			#size-cells = <0x00>;
			compatible = "allwinner,sun20i-twi";
			device_type = "twi3";
			reg = <0x00 0x2502c00 0x00 0x400>;
			interrupts-extended = <0x0a 0x1c 0x04>;
			clocks = <0x01 0x48>;
			resets = <0x01 0x1b>;
			clock-names = "bus";
			clock-frequency = <0x61a80>;
			dmas = <0x20 0x2e 0x20 0x2e>;
			dma-names = "tx\0rx";
			status = "disabled";
			pinctrl-0 = <0x2d>;
			pinctrl-1 = <0x2e>;
			pinctrl-names = "default\0sleep";
		};
 
		ledc@2008000 {
			#address-cells = <0x01>;
			#size-cells = <0x00>;
			compatible = "allwinner,sunxi-leds";
			reg = <0x00 0x2008000 0x00 0x400>;
			interrupts-extended = <0x0a 0x24 0x04>;
			interrupt-names = "ledcirq";
			clocks = <0x01 0x7d 0x01 0x7e>;
			clock-names = "clk_ledc\0clk_cpuapb";
			dmas = <0x20 0x2a 0x20 0x2a>;
			dma-names = "rx\0tx";
			resets = <0x01 0x3d>;
			reset-names = "ledc_reset";
			status = "disabled";
			pinctrl-names = "default\0sleep";
			pinctrl-0 = <0x2f>;
			pinctrl-1 = <0x30>;
			led_count = <0x0c>;
			output_mode = "GRB";
			reset_ns = <0x54>;
			t1h_ns = <0x320>;
			t1l_ns = <0x140>;
			t0h_ns = <0x12c>;
			t0l_ns = <0x320>;
			wait_time0_ns = <0x54>;
			wait_time1_ns = <0x54>;
			wait_data_time_ns = <0x927c0>;
		};
 
		pwm@2000c00 {
			#pwm-cells = <0x03>;
			compatible = "allwinner,sunxi-pwm";
			reg = <0x00 0x2000c00 0x00 0x3ff>;
			clocks = <0x01 0x2f>;
			resets = <0x01 0x0d>;
			pwm-number = <0x08>;
			pwm-base = <0x00>;
			sunxi-pwms = <0x31 0x32 0x33 0x34 0x35 0x36 0x37 0x38>;
			phandle = <0x6a>;
		};
 
		keyboard@2009800 {
			compatible = "allwinner,keyboard_1350mv";
			reg = <0x00 0x2009800 0x00 0x400>;
			interrupts-extended = <0x0a 0x4d 0x01>;
			clocks = <0x01 0x6b>;
			resets = <0x01 0x31>;
			key_cnt = <0x05>;
			key0 = <0xd2 0x160>;
			key1 = <0x19a 0x72>;
			key2 = <0x24e 0x8b>;
			key3 = <0x2ee 0x1c>;
			key4 = <0x370 0xac>;
			status = "okay";
			wakeup-source;
		};
 
		sid@3006000 {
			compatible = "allwinner,sun20iw1p1-sid\0allwinner,sunxi-sid";
			reg = <0x00 0x3006000 0x00 0x1000>;
			#address-cells = <0x01>;
			#size-cells = <0x01>;
 
			chipid {
				reg = <0x00 0x00>;
				offset = <0x200>;
				size = <0x10>;
			};
 
			oem {
				reg = <0x00 0x00>;
				offset = <0x238>;
				size = <0x08>;
			};
 
			secure_status {
				reg = <0x00 0x00>;
				offset = <0x210>;
				size = <0x04>;
			};
 
			speedbin@00 {
				reg = <0x00 0x04>;
				phandle = <0x05>;
			};
 
			cpubin@28 {
				reg = <0x28 0x04>;
				phandle = <0x06>;
			};
 
			calib@14 {
				reg = <0x14 0x08>;
				phandle = <0x39>;
			};
		};
 
		gpadc@2009000 {
			compatible = "allwinner,sunxi-gpadc";
			reg = <0x00 0x2009000 0x00 0x400>;
			interrupts-extended = <0x0a 0x49 0x04>;
			clocks = <0x01 0x53>;
			clock-names = "bus";
			resets = <0x01 0x22>;
			status = "disabled";
			channel_num = <0x02>;
			channel_select = <0x03>;
			channel_data_select = <0x03>;
			channel_compare_select = <0x03>;
			channel_cld_select = <0x03>;
			channel_chd_select = <0x03>;
			channel0_compare_lowdata = <0x19f0a0>;
			channel0_compare_higdata = <0x124f80>;
			channel1_compare_lowdata = <0x704e0>;
			channel1_compare_higdata = <0x124f80>;
		};
 
		ths@02009400 {
			compatible = "allwinner,sun20iw1p1-ths";
			reg = <0x00 0x2009400 0x00 0x400>;
			clocks = <0x01 0x54>;
			clock-names = "bus";
			resets = <0x01 0x23>;
			nvmem-cells = <0x39>;
			nvmem-cell-names = "calibration";
			#thermal-sensor-cells = <0x01>;
			phandle = <0x07>;
		};
 
		tpadc@2009c00 {
			compatible = "allwinner,tp_key";
			reg = <0x00 0x2009c00 0x00 0x400>;
			interrupts-extended = <0x0a 0x4e 0x04>;
			clocks = <0x01 0x82 0x01 0x83>;
			clock-names = "mod\0bus";
			clock-frequency = <0xf4240>;
			resets = <0x01 0x3f>;
			status = "disabled";
		};
 
		rtp@2009c00 {
			compatible = "allwinner,sun8i-ts";
			reg = <0x00 0x2009c00 0x00 0x400>;
			clocks = <0x01 0x82 0x01 0x83>;
			clock-names = "mod\0bus";
			clock-frequency = <0xf4240>;
			resets = <0x01 0x3f>;
			interrupts-extended = <0x0a 0x4e 0x04>;
			allwinner,tp-sensitive-adjust = <0x0f>;
			allwinner,filter-type = <0x01>;
			allwinner,ts-attached;
			status = "disabled";
		};
 
		codec@2030000 {
			#sound-dai-cells = <0x00>;
			compatible = "allwinner,sunxi-internal-codec";
			reg = <0x00 0x2030000 0x00 0x34c>;
			clocks = <0x01 0x0f 0x01 0x14 0x01 0x61 0x01 0x62 0x01 0x63>;
			clock-names = "pll_audio0\0pll_audio1_div5\0audio_clk_dac\0audio_clk_adc\0audio_clk_bus";
			resets = <0x01 0x29>;
			rx_sync_en = <0x00>;
			device_type = "codec";
			status = "okay";
			mic1gain = <0x13>;
			mic2gain = <0x13>;
			mic3gain = <0x13>;
			adcdrc_cfg = <0x00>;
			adchpf_cfg = <0x01>;
			dacdrc_cfg = <0x00>;
			dachpf_cfg = <0x00>;
			digital_vol = <0x00>;
			lineout_vol = <0x1a>;
			headphonegain = <0x03>;
			pa_level = <0x01>;
			pa_pwr_level = <0x01>;
			pa_msleep_time = <0x78>;
			gpio-spk = <0x1d 0x04 0x01 0x00>;
			gpio-spk-pwr = <0x1d 0x01 0x02 0x00>;
			phandle = <0x3a>;
		};
 
		dummy_cpudai@203034c {
			compatible = "allwinner,sunxi-dummy-cpudai";
			reg = <0x00 0x203034c 0x00 0x04>;
			tx_fifo_size = <0x80>;
			rx_fifo_size = <0x100>;
			dac_txdata = <0x2030020>;
			adc_txdata = <0x2030040>;
			playback_cma = <0x80>;
			capture_cma = <0x100>;
			device_type = "cpudai";
			dmas = <0x20 0x07 0x20 0x07>;
			dma-names = "tx\0rx";
			status = "okay";
			phandle = <0x3b>;
		};
 
		sound@2030340 {
			compatible = "allwinner,sunxi-codec-machine";
			reg = <0x00 0x2030340 0x00 0x04>;
			interrupts-extended = <0x0a 0x29 0x04>;
			sunxi,audio-codec = <0x3a>;
			sunxi,cpudai-controller = <0x3b>;
			device_type = "sndcodec";
			status = "okay";
			hp_detect_case = <0x01>;
			jack_enable = <0x01>;
		};
 
		rpaf-dsp@203034c {
			compatible = "allwinner,rpaf-dsp0";
			device_type = "sunxi_rpaf_dsp0";
			dsp_id = <0x00>;
			status = "okay";
		};
 
		dmic@2031000 {
			#sound-dai-cells = <0x00>;
			compatible = "allwinner,sunxi-dmic";
			reg = <0x00 0x2031000 0x00 0x50>;
			clocks = <0x01 0x0f 0x01 0x5f 0x01 0x60>;
			clock-names = "pll_audio\0dmic\0dmic_bus";
			resets = <0x01 0x28>;
			dmas = <0x20 0x08>;
			dma-names = "rx";
			interrupts-extended = <0x0a 0x28 0x04>;
			clk_parent = <0x01>;
			capture_cma = <0x100>;
			data_vol = <0xb0>;
			rx_chmap = <0x76543210>;
			rx_sync_en = <0x00>;
			device_type = "dmic";
			status = "disabled";
			pinctrl-names = "default\0sleep";
			pinctrl-0 = <0x3c>;
			pinctrl-1 = <0x3d>;
			phandle = <0x3e>;
		};
 
		sound@2031050 {
			#sound-dai-cells = <0x00>;
			compatible = "dmic-codec";
			reg = <0x00 0x2031050 0x00 0x04>;
			num-channels = <0x08>;
			status = "disabled";
			phandle = <0x3f>;
		};
 
		sounddmic@2031060 {
			reg = <0x00 0x2031060 0x00 0x04>;
			compatible = "sunxi,simple-audio-card";
			simple-audio-card,name = "snddmic";
			simple-audio-card,capture_only;
			status = "disabled";
 
			simple-audio-card,cpu {
				sound-dai = <0x3e>;
			};
 
			simple-audio-card,codec {
				sound-dai = <0x3f>;
			};
		};
 
		daudio@2032000 {
			#sound-dai-cells = <0x00>;
			compatible = "allwinner,sunxi-daudio";
			reg = <0x00 0x2032000 0x00 0xa0>;
			clocks = <0x01 0x0f 0x01 0x55 0x01 0x59>;
			clock-names = "pll_audio\0i2s0\0i2s0_bus";
			resets = <0x01 0x24>;
			dmas = <0x20 0x03 0x20 0x03>;
			dma-names = "tx\0rx";
			interrupts-extended = <0x0a 0x2a 0x04>;
			sign_extend = <0x00>;
			tx_data_mode = <0x00>;
			rx_data_mode = <0x00>;
			msb_lsb_first = <0x00>;
			pcm_lrck_period = <0x80>;
			slot_width_select = <0x20>;
			frametype = <0x00>;
			tdm_config = <0x01>;
			tdm_num = <0x00>;
			mclk_div = <0x01>;
			clk_parent = <0x01>;
			capture_cma = <0x80>;
			playback_cma = <0x80>;
			tx_num = <0x04>;
			tx_chmap1 = <0x76543210>;
			tx_chmap0 = <0xfedcba98>;
			rx_num = <0x04>;
			rx_chmap3 = <0x3020100>;
			rx_chmap2 = <0x7060504>;
			rx_chmap1 = <0xb0a0908>;
			rx_chmap0 = <0xf0e0d0c>;
			asrc_function_en = <0x00>;
			rx_sync_en = <0x00>;
			device_type = "daudio0";
			status = "disabled";
			pinctrl-names = "default\0sleep";
			pinctrl-0 = <0x40 0x41 0x42>;
			pinctrl-1 = <0x43>;
			pinctrl_used = <0x00>;
			phandle = <0x44>;
		};
 
		sounddaudio0@20320a0 {
			reg = <0x00 0x20320a0 0x00 0x04>;
			compatible = "sunxi,simple-audio-card";
			simple-audio-card,name = "snddaudio0";
			simple-audio-card,format = "i2s";
			status = "disabled";
 
			simple-audio-card,cpu {
				sound-dai = <0x44>;
			};
 
			simple-audio-card,codec {
			};
		};
 
		daudio@2033000 {
			#sound-dai-cells = <0x00>;
			compatible = "allwinner,sunxi-daudio";
			reg = <0x00 0x2033000 0x00 0xa0>;
			clocks = <0x01 0x0f 0x01 0x56 0x01 0x5a>;
			clock-names = "pll_audio\0i2s1\0i2s1_bus";
			resets = <0x01 0x25>;
			dmas = <0x20 0x04 0x20 0x04>;
			dma-names = "tx\0rx";
			interrupts-extended = <0x0a 0x2b 0x04>;
			sign_extend = <0x00>;
			tx_data_mode = <0x00>;
			rx_data_mode = <0x00>;
			msb_lsb_first = <0x00>;
			pcm_lrck_period = <0x80>;
			slot_width_select = <0x20>;
			frametype = <0x00>;
			tdm_config = <0x01>;
			tdm_num = <0x01>;
			mclk_div = <0x01>;
			clk_parent = <0x01>;
			capture_cma = <0x80>;
			playback_cma = <0x80>;
			tx_num = <0x04>;
			tx_chmap1 = <0x76543210>;
			tx_chmap0 = <0xfedcba98>;
			rx_num = <0x04>;
			rx_chmap3 = <0x3020100>;
			rx_chmap2 = <0x7060504>;
			rx_chmap1 = <0xb0a0908>;
			rx_chmap0 = <0xf0e0d0c>;
			asrc_function_en = <0x00>;
			rx_sync_en = <0x00>;
			device_type = "daudio1";
			status = "disabled";
			pinctrl-names = "default\0sleep";
			pinctrl-0 = <0x45 0x46 0x47>;
			pinctrl-1 = <0x48>;
			pinctrl_used = <0x00>;
			phandle = <0x49>;
		};
 
		sounddaudio1@20330a0 {
			reg = <0x00 0x20330a0 0x00 0x04>;
			compatible = "sunxi,simple-audio-card";
			simple-audio-card,name = "snddaudio1";
			simple-audio-card,format = "i2s";
			status = "disabled";
 
			simple-audio-card,cpu {
				sound-dai = <0x49>;
			};
 
			simple-audio-card,codec {
			};
		};
 
		daudio@2034000 {
			#sound-dai-cells = <0x00>;
			compatible = "allwinner,sunxi-daudio";
			reg = <0x00 0x2034000 0x00 0xa0>;
			clocks = <0x01 0x0f 0x01 0x57 0x01 0x5b 0x01 0x11 0x01 0x58>;
			resets = <0x01 0x26>;
			dmas = <0x20 0x05 0x20 0x05>;
			dma-names = "tx\0rx";
			interrupts-extended = <0x0a 0x2c 0x04>;
			sign_extend = <0x00>;
			tx_data_mode = <0x00>;
			rx_data_mode = <0x00>;
			msb_lsb_first = <0x00>;
			pcm_lrck_period = <0x20>;
			slot_width_select = <0x20>;
			frametype = <0x00>;
			tdm_config = <0x01>;
			tdm_num = <0x02>;
			mclk_div = <0x00>;
			clk_parent = <0x01>;
			capture_cma = <0x80>;
			playback_cma = <0x80>;
			tx_num = <0x04>;
			tx_chmap1 = <0x76543210>;
			tx_chmap0 = <0xfedcba98>;
			rx_num = <0x04>;
			rx_chmap3 = <0x3020100>;
			rx_chmap2 = <0x7060504>;
			rx_chmap1 = <0xb0a0908>;
			rx_chmap0 = <0xf0e0d0c>;
			asrc_function_en = <0x00>;
			rx_sync_en = <0x00>;
			device_type = "daudio2";
			status = "okay";
			pinctrl-names = "default\0sleep";
			pinctrl-0;
			pinctrl-1;
			pinctrl_used = <0x00>;
			daudio_type = <0x01>;
			phandle = <0x4a>;
		};
 
		sounddaudio2@20340a0 {
			reg = <0x00 0x20340a0 0x00 0x04>;
			compatible = "sunxi,simple-audio-card";
			simple-audio-card,name = "sndhdmi";
			simple-audio-card,format = "i2s";
			status = "okay";
 
			simple-audio-card,cpu {
				sound-dai = <0x4a>;
			};
 
			simple-audio-card,codec {
				sound-dai = <0x4b>;
			};
		};
 
		hdmiaudio@20340a4 {
			#sound-dai-cells = <0x00>;
			reg = <0x00 0x20340a4 0x00 0x04>;
			compatible = "allwinner,sunxi-hdmiaudio";
			status = "okay";
			phandle = <0x4b>;
		};
 
		spdif@2036000 {
			#sound-dai-cells = <0x00>;
			compatible = "allwinner,sunxi-spdif";
			reg = <0x00 0x2036000 0x00 0x58>;
			clocks = <0x01 0x11 0x01 0x5c 0x01 0x5e 0x01 0x12 0x01 0x14 0x01 0x04 0x01 0x5d>;
			clock-names = "pll_audio0\0spdif\0spdif_bus\0pll_audio1\0pll_audio1_div5\0pll_periph\0spdif_rx";
			resets = <0x01 0x27>;
			dmas = <0x20 0x02 0x20 0x02>;
			dma-names = "tx\0rx";
			interrupts-extended = <0x0a 0x29 0x04>;
			clk_parent = <0x01>;
			playback_cma = <0x80>;
			capture_cma = <0x80>;
			rx_sync_en = <0x00>;
			device_type = "spdif";
			status = "disabled";
			pinctrl-names = "default\0sleep";
			pinctrl-0 = <0x4c>;
			pinctrl-1 = <0x4d>;
			phandle = <0x4e>;
		};
 
		soundspdif@2036040 {
			reg = <0x00 0x2036040 0x00 0x04>;
			compatible = "sunxi,simple-audio-card";
			simple-audio-card,name = "sndspdif";
			status = "disabled";
 
			simple-audio-card,cpu {
				sound-dai = <0x4e>;
			};
 
			simple-audio-card,codec {
			};
		};
 
		g2d@5410000 {
			compatible = "allwinner,sunxi-g2d";
			reg = <0x00 0x5410000 0x00 0x3ffff>;
			interrupts-extended = <0x0a 0x69 0x04>;
			clocks = <0x01 0x22 0x01 0x21 0x01 0x37>;
			clock-names = "bus\0g2d\0mbus_g2d";
			resets = <0x01 0x03>;
			iommus = <0x1a 0x03 0x01>;
			status = "okay";
		};
 
		disp@5000000 {
			compatible = "allwinner,sunxi-disp";
			reg = <0x00 0x5000000 0x00 0x3fffff 0x00 0x5460000 0x00 0xfff 0x00 0x5461000 0x00 0xfff 0x00 0x5470000 0x00 0xfff 0x00 0x5450000 0x00 0x1fff>;
			interrupts-extended = <0x0a 0x6a 0x04 0x0a 0x6b 0x04 0x0a 0x6c 0x04>;
			clocks = <0x01 0x1d 0x01 0x1d 0x01 0x1e 0x01 0x1e 0x01 0x6c 0x01 0x6c 0x01 0x71 0x01 0x72 0x01 0x73 0x01 0x75 0x01 0x74 0x01 0x76 0x01 0x71 0x01 0x72>;
			clock-names = "clk_de0\0clk_de1\0clk_bus_de0\0clk_bus_de1\0clk_bus_dpss_top0\0clk_bus_dpss_top1\0clk_mipi_dsi0\0clk_bus_mipi_dsi0\0clk_tcon0\0clk_tcon1\0clk_bus_tcon0\0clk_bus_tcon1\0clk_mipi_dsi0\0clk_bus_mipi_dsi0";
			resets = <0x01 0x01 0x01 0x01 0x01 0x32 0x01 0x32 0x01 0x35 0x01 0x36 0x01 0x37 0x01 0x38>;
			reset-names = "rst_bus_de0\0rst_bus_de1\0rst_bus_dpss_top0\0rst_bus_dpss_top1\0rst_bus_mipi_dsi0\0rst_bus_tcon0\0rst_bus_tcon1\0rst_bus_lvds0";
			assigned-clocks = <0x01 0x1d 0x01 0x71 0x01 0x73 0x01 0x75>;
			assigned-clock-parents = <0x01 0x05 0x01 0x04 0x01 0x0a 0x01 0x0d>;
			assigned-clock-rates = <0x11e1a300 0x8f0d180 0x00 0x00>;
			boot_disp = <0x00>;
			boot_disp1 = <0x00>;
			boot_disp2 = <0x00>;
			fb_base = <0x00>;
			iommus = <0x1a 0x02 0x00>;
			status = "okay";
			disp_init_enable = <0x01>;
			disp_mode = <0x00>;
			screen0_output_type = <0x01>;
			screen0_output_mode = <0x04>;
			screen1_output_type = <0x03>;
			screen1_output_mode = <0x0a>;
			screen1_output_format = <0x00>;
			screen1_output_bits = <0x00>;
			screen1_output_eotf = <0x04>;
			screen1_output_cs = <0x101>;
			screen1_output_dvi_hdmi = <0x02>;
			screen1_output_range = <0x02>;
			screen1_output_scan = <0x00>;
			screen1_output_aspect_ratio = <0x08>;
			dev0_output_type = <0x01>;
			dev0_output_mode = <0x04>;
			dev0_screen_id = <0x00>;
			dev0_do_hpd = <0x00>;
			dev1_output_type = <0x04>;
			dev1_output_mode = <0x0a>;
			dev1_screen_id = <0x01>;
			dev1_do_hpd = <0x01>;
			def_output_dev = <0x00>;
			hdmi_mode_check = <0x01>;
			fb0_format = <0x00>;
			fb0_width = <0x00>;
			fb0_height = <0x00>;
			fb1_format = <0x00>;
			fb1_width = <0x00>;
			fb1_height = <0x00>;
			chn_cfg_mode = <0x01>;
			disp_para_zone = <0x01>;
		};
 
		ve@1c0e000 {
			compatible = "allwinner,sunxi-cedar-ve";
			reg = <0x00 0x1c0e000 0x00 0x1000 0x00 0x3000000 0x00 0x10 0x00 0x3001000 0x00 0x1000>;
			interrupts-extended = <0x0a 0x52 0x04>;
			clocks = <0x01 0x26 0x01 0x25 0x01 0x33>;
			clock-names = "bus_ve\0ve\0mbus_ve";
			resets = <0x01 0x05>;
			iommus = <0x1a 0x00 0x01>;
			status = "okay";
		};
 
		msgbox@0601f000 {
			compatible = "sunxi,msgbox-amp";
			reg = <0x00 0x3003000 0x00 0x1000 0x00 0x1701000 0x00 0x1000 0x00 0x601f000 0x00 0x1000>;
			interrupts-extended = <0x0a 0x90 0x04 0x0a 0x66 0x04 0x0a 0x8c 0x04>;
			clocks = <0x01 0x2a>;
			rpmsg_id = "sunxi,dsp-msgbox\0sunxi,dsp-power-msgbox";
			resets = <0x01 0x09>;
			reset-names = "rst";
			msgbox_amp_counts = <0x03>;
			msgbox_amp_local = <0x02>;
			rpmsg_amp_remote-0 = <0x01>;
			rpmsg_read_channel-0 = <0x02>;
			rpmsg_write_channel-0 = <0x02>;
			rpmsg_amp_remote-1 = <0x01>;
			rpmsg_read_channel-1 = <0x00>;
			rpmsg_write_channel-1 = <0x00>;
		};
 
		lcd0@1c0c000 {
			compatible = "allwinner,sunxi-lcd0";
			reg = <0x00 0x1c0c000 0x00 0x00>;
			pinctrl-names = "active\0sleep";
			status = "okay";
			lcd_used = <0x01>;
			lcd_driver_name = "cwu50";
			lcd_backlight = <0x32>;
			lcd_if = <0x04>;
			lcd_x = <0x2d0>;
			lcd_y = <0x500>;
			lcd_width = <0x5a>;
			lcd_height = <0xa0>;
			lcd_dclk_freq = <0x3e>;
			lcd_pwm_used = <0x01>;
			lcd_pwm_ch = <0x02>;
			lcd_pwm_freq = <0x3e8>;
			lcd_pwm_pol = <0x00>;
			lcd_pwm_max_limit = <0xff>;
			lcd_hbp = <0x28>;
			lcd_ht = <0x316>;
			lcd_hspw = <0x14>;
			lcd_vbp = <0x12>;
			lcd_vt = <0x51a>;
			lcd_vspw = <0x02>;
			lcd_dsi_if = <0x00>;
			lcd_dsi_lane = <0x04>;
			lcd_lvds_if = <0x00>;
			lcd_lvds_colordepth = <0x00>;
			lcd_lvds_mode = <0x00>;
			lcd_frm = <0x00>;
			lcd_hv_clk_phase = <0x00>;
			lcd_hv_sync_polarity = <0x00>;
			lcd_io_phase = <0x00>;
			lcd_gamma_en = <0x00>;
			lcd_bright_curve_en = <0x00>;
			lcd_cmap_en = <0x00>;
			lcd_fsync_en = <0x00>;
			lcd_fsync_act_time = <0x3e8>;
			lcd_fsync_dis_time = <0x3e8>;
			lcd_fsync_pol = <0x00>;
			deu_mode = <0x00>;
			lcdgamma4iep = <0x16>;
			smart_color = <0x5a>;
			lcd_gpio_0 = <0x1d 0x03 0x13 0x00>;
			pinctrl-0 = <0x4f>;
			pinctrl-1 = <0x50>;
		};
 
		sdmmc@4022000 {
			compatible = "allwinner,sunxi-mmc-v4p6x";
			device_type = "sdc2";
			reg = <0x00 0x4022000 0x00 0x1000>;
			interrupts-extended = <0x0a 0x3a 0x04>;
			clocks = <0x0b 0x01 0x05 0x01 0x3b 0x01 0x3e>;
			clock-names = "osc24m\0pll_periph\0mmc\0ahb";
			resets = <0x01 0x11>;
			reset-names = "rst";
			pinctrl-names = "default\0sleep";
			pinctrl-0 = <0x51>;
			pinctrl-1 = <0x52>;
			bus-width = <0x04>;
			req-page-count = <0x02>;
			cap-mmc-highspeed;
			cap-cmd23;
			mmc-cache-ctrl;
			non-removable;
			max-frequency = <0x8f0d180>;
			cap-erase;
			mmc-high-capacity-erase-size;
			no-sdio;
			no-sd;
			sdc_tm4_sm0_freq0 = <0x00>;
			sdc_tm4_sm0_freq1 = <0x00>;
			sdc_tm4_sm1_freq0 = <0x00>;
			sdc_tm4_sm1_freq1 = <0x00>;
			sdc_tm4_sm2_freq0 = <0x00>;
			sdc_tm4_sm2_freq1 = <0x00>;
			sdc_tm4_sm3_freq0 = <0x5000000>;
			sdc_tm4_sm3_freq1 = <0x05>;
			sdc_tm4_sm4_freq0 = <0x50000>;
			sdc_tm4_sm4_freq1 = <0x04>;
			sdc_tm4_sm4_freq0_cmd = <0x00>;
			sdc_tm4_sm4_freq1_cmd = <0x00>;
			mmc-ddr-1_8v;
			mmc-hs200-1_8v;
			ctl-spec-caps = <0x308>;
			sunxi-power-save-mode;
			sunxi-dis-signal-vol-sw;
			mmc-bootpart-noacc;
			status = "disabled";
		};
 
		sdmmc@4020000 {
			compatible = "allwinner,sunxi-mmc-v5p3x";
			device_type = "sdc0";
			reg = <0x00 0x4020000 0x00 0x1000>;
			interrupts-extended = <0x0a 0x38 0x04>;
			clocks = <0x0b 0x01 0x05 0x01 0x39 0x01 0x3c>;
			clock-names = "osc24m\0pll_periph\0mmc\0ahb";
			resets = <0x01 0x0f>;
			reset-names = "rst";
			pinctrl-names = "default\0mmc_1v8\0sleep\0uart_jtag";
			pinctrl-0 = <0x53>;
			pinctrl-1 = <0x54>;
			pinctrl-2 = <0x55>;
			pinctrl-3 = <0x56 0x57>;
			max-frequency = <0x8f0d180>;
			bus-width = <0x04>;
			req-page-count = <0x02>;
			cap-sd-highspeed;
			cap-wait-while-busy;
			no-sdio;
			no-mmc;
			status = "okay";
			cd-gpios = <0x1d 0x05 0x06 0x11>;
			non-removable;
			cd-inverted;
			cd-used-24M;
			sunxi-power-save-mode;
			ctl-spec-caps = <0x08>;
		};
 
		sdmmc@4021000 {
			compatible = "allwinner,sunxi-mmc-v5p3x";
			device_type = "sdc1";
			reg = <0x00 0x4021000 0x00 0x1000>;
			interrupts-extended = <0x0a 0x39 0x04>;
			clocks = <0x0b 0x01 0x05 0x01 0x3a 0x01 0x3d>;
			clock-names = "osc24m\0pll_periph\0mmc\0ahb";
			resets = <0x01 0x10>;
			reset-names = "rst";
			pinctrl-names = "default\0sleep";
			pinctrl-0 = <0x58>;
			pinctrl-1 = <0x59>;
			max-frequency = <0x8f0d180>;
			bus-width = <0x04>;
			cap-sd-highspeed;
			no-mmc;
			keep-power-in-suspend;
			sunxi-dly-52M-ddr4 = <0x01 0x00 0x00 0x00 0x02>;
			sunxi-dly-104M = <0x01 0x00 0x00 0x00 0x01>;
			sunxi-dly-208M = <0x01 0x00 0x00 0x00 0x01>;
			status = "okay";
			vmmc-supply = <0x5a>;
			vqmmc-supply = <0x5b>;
			mmc-pwrseq = <0x5c>;
			no-sd;
			cap-sdio-irq;
			ignore-pm-notify;
			ctl-spec-caps = <0x08>;
 
			sdio-wifi@1 {
				reg = <0x01>;
				interrupt-parent = <0x1d>;
				interrupts = <0x06 0x0a 0x08>;
				interrupt-names = "host-wake";
			};
		};
 
		hdmi@5500000 {
			compatible = "allwinner,sunxi-hdmi";
			reg = <0x00 0x5500000 0x00 0xfffff>;
			interrupts-extended = <0x0a 0x5d 0x04>;
			clocks = <0x01 0x70 0x01 0x6d 0x01 0x6e 0x01 0x75>;
			clock-names = "clk_bus_hdmi\0clk_ddc\0clk_cec\0clk_tcon_tv";
			resets = <0x01 0x33 0x01 0x34>;
			reset-names = "rst_bus_sub\0rst_bus_main";
			assigned-clocks = <0x01 0x6e>;
			assigned-clock-parents = <0x01 0x6f>;
			assigned-clock-rates = <0x00>;
			status = "okay";
			hdmi_used = <0x01>;
			hdmi_power_cnt = <0x00>;
			hdmi_cts_compatibility = <0x01>;
			hdmi_hdcp_enable = <0x01>;
			hdmi_hdcp22_enable = <0x00>;
			hdmi_cec_support = <0x01>;
			hdmi_cec_super_standby = <0x00>;
			ddc_en_io_ctrl = <0x00>;
			power_io_ctrl = <0x00>;
		};
 
		usbc0@0 {
			device_type = "usbc0";
			compatible = "allwinner,sunxi-otg-manager";
			usb_port_type = <0x00>;
			usb_detect_type = <0x01>;
			usb_id_gpio = <0x1d 0x03 0x15 0x00>;
			usb_det_vbus_gpio;
			usb_regulator_io = "nocare";
			usb_wakeup_suspend = <0x00>;
			usb_luns = <0x03>;
			usb_serial_unique = <0x00>;
			usb_serial_number = "20080411";
			rndis_wceis = <0x01>;
			status = "okay";
			usb_detect_mode = <0x00>;
			enable-active-high;
		};
 
		udc-controller@0x04100000 {
			compatible = "allwinner,sunxi-udc";
			reg = <0x00 0x4100000 0x00 0x1000 0x00 0x00 0x00 0x100>;
			interrupts-extended = <0x0a 0x2d 0x04>;
			clocks = <0x01 0x6a>;
			clock-names = "bus_otg";
			resets = <0x01 0x30 0x01 0x2a>;
			reset-names = "otg\0phy";
			status = "okay";
		};
 
		ehci0-controller@0x04101000 {
			compatible = "allwinner,sunxi-ehci0";
			reg = <0x00 0x4101000 0x00 0xfff 0x00 0x00 0x00 0x100 0x00 0x4100000 0x00 0x1000>;
			interrupts-extended = <0x0a 0x2e 0x04>;
			clocks = <0x01 0x68>;
			clock-names = "bus_hci";
			resets = <0x01 0x2e 0x01 0x2a>;
			reset-names = "hci\0phy";
			hci_ctrl_no = <0x00>;
			status = "okay";
			drvvbus-supply = <0x5d>;
		};
 
		ohci0-controller@0x04101400 {
			compatible = "allwinner,sunxi-ohci0";
			reg = <0x00 0x4101400 0x00 0xfff 0x00 0x00 0x00 0x100 0x00 0x4100000 0x00 0x1000>;
			interrupts-extended = <0x0a 0x2f 0x04>;
			clocks = <0x01 0x66 0x01 0x64>;
			clock-names = "bus_hci\0ohci";
			resets = <0x01 0x2c 0x01 0x2a>;
			reset-names = "hci\0phy";
			hci_ctrl_no = <0x00>;
			status = "okay";
			drvvbus-supply = <0x5d>;
		};
 
		usbc1@0 {
			device_type = "usbc1";
			usb_regulator_io = "nocare";
			usb_wakeup_suspend = <0x00>;
			status = "okay";
		};
 
		ehci1-controller@0x04200000 {
			compatible = "allwinner,sunxi-ehci1";
			reg = <0x00 0x4200000 0x00 0xfff 0x00 0x00 0x00 0x100 0x00 0x4100000 0x00 0x1000>;
			interrupts-extended = <0x0a 0x31 0x04>;
			clocks = <0x01 0x69>;
			clock-names = "bus_hci";
			resets = <0x01 0x2f 0x01 0x2b>;
			reset-names = "hci\0phy";
			hci_ctrl_no = <0x01>;
			status = "okay";
		};
 
		ohci1-controller@0x04200400 {
			compatible = "allwinner,sunxi-ohci1";
			reg = <0x00 0x4200400 0x00 0xfff 0x00 0x00 0x00 0x100 0x00 0x4100000 0x00 0x1000>;
			interrupts-extended = <0x0a 0x32 0x04>;
			clocks = <0x01 0x67 0x01 0x65>;
			clock-names = "bus_hci\0ohci";
			resets = <0x01 0x2d 0x01 0x2b>;
			reset-names = "hci\0phy";
			hci_ctrl_no = <0x01>;
			status = "okay";
		};
 
		pwm0@2000c10 {
			compatible = "allwinner,sunxi-pwm0";
			reg = <0x00 0x2000c10 0x00 0x04>;
			reg_base = <0x2000c00>;
			pinctrl-names = "active\0sleep";
			pinctrl-0 = <0x5e>;
			pinctrl-1 = <0x5f>;
			status = "okay";
			phandle = <0x31>;
		};
 
		pwm1@2000c11 {
			compatible = "allwinner,sunxi-pwm1";
			reg = <0x00 0x2000c11 0x00 0x04>;
			reg_base = <0x2000c00>;
			phandle = <0x32>;
		};
 
		pwm2@2000c12 {
			compatible = "allwinner,sunxi-pwm2";
			reg = <0x00 0x2000c12 0x00 0x04>;
			reg_base = <0x2000c00>;
			pinctrl-names = "active\0sleep";
			pinctrl-0 = <0x60>;
			pinctrl-1 = <0x61>;
			status = "okay";
			phandle = <0x33>;
		};
 
		pwm3@2000c13 {
			compatible = "allwinner,sunxi-pwm3";
			reg = <0x00 0x2000c13 0x00 0x04>;
			reg_base = <0x2000c00>;
			phandle = <0x34>;
		};
 
		pwm4@2000c14 {
			compatible = "allwinner,sunxi-pwm4";
			reg = <0x00 0x2000c14 0x00 0x04>;
			reg_base = <0x2000c00>;
			phandle = <0x35>;
		};
 
		pwm5@2000c15 {
			compatible = "allwinner,sunxi-pwm5";
			reg = <0x00 0x2000c15 0x00 0x04>;
			reg_base = <0x2000c00>;
			phandle = <0x36>;
		};
 
		pwm6@2000c16 {
			compatible = "allwinner,sunxi-pwm6";
			reg = <0x00 0x2000c16 0x00 0x04>;
			reg_base = <0x2000c00>;
			phandle = <0x37>;
		};
 
		pwm7@2000c17 {
			compatible = "allwinner,sunxi-pwm7";
			reg = <0x00 0x2000c17 0x00 0x04>;
			reg_base = <0x2000c00>;
			phandle = <0x38>;
		};
 
		lcd_fb0@0 {
			compatible = "allwinner,sunxi-lcd_fb0";
			pinctrl-names = "active\0sleep";
			status = "disabled";
		};
 
		vind@5800800 {
			compatible = "allwinner,sunxi-vin-media\0simple-bus";
			#address-cells = <0x02>;
			#size-cells = <0x02>;
			ranges;
			device_id = <0x00>;
			csi_top = <0x1406f400>;
			csi_isp = <0x137d9fc0>;
			reg = <0x00 0x5800800 0x00 0x200 0x00 0x5800000 0x00 0x800>;
			clocks = <0x01 0x7f 0x01 0x0c 0x01 0x80 0x0b 0x01 0x0b 0x01 0x81 0x01 0x36>;
			clock-names = "csi_top\0csi_top_src\0csi_mclk0\0csi_mclk0_24m\0csi_mclk0_pll\0csi_bus\0csi_mbus";
			resets = <0x01 0x3e>;
			reset-names = "csi_ret";
			pinctrl-names = "mclk0-default\0mclk0-sleep";
			pinctrl-0 = <0x62>;
			pinctrl-1 = <0x63>;
			status = "okay";
 
			csi@5801000 {
				compatible = "allwinner,sunxi-csi";
				reg = <0x00 0x5801000 0x00 0x1000>;
				interrupts-extended = <0x0a 0x74 0x04>;
				pinctrl-names = "default\0sleep";
				pinctrl-0 = <0x64>;
				pinctrl-1 = <0x65>;
				device_id = <0x00>;
				iommus = <0x1a 0x01 0x01>;
				status = "okay";
			};
 
			isp@5809410 {
				compatible = "allwinner,sunxi-isp";
				reg = <0x00 0x5809410 0x00 0x10>;
				device_id = <0xfe>;
				status = "okay";
			};
 
			isp@5809420 {
				compatible = "allwinner,sunxi-isp";
				reg = <0x00 0x5809420 0x00 0x10>;
				device_id = <0xff>;
				status = "okay";
			};
 
			scaler@5809430 {
				compatible = "allwinner,sunxi-scaler";
				reg = <0x00 0x5809430 0x00 0x10>;
				device_id = <0xfe>;
				status = "okay";
			};
 
			scaler@5809440 {
				compatible = "allwinner,sunxi-scaler";
				reg = <0x00 0x5809440 0x00 0x10>;
				device_id = <0xff>;
				status = "okay";
			};
 
			actuator@5809450 {
				compatible = "allwinner,sunxi-actuator";
				device_type = "actuator0";
				reg = <0x00 0x5809450 0x00 0x10>;
				actuator0_name = "ad5820_act";
				actuator0_slave = <0x18>;
				actuator0_af_pwdn;
				actuator0_afvdd = "afvcc-csi";
				actuator0_afvdd_vol = <0x2ab980>;
				status = "disabled";
				phandle = <0x67>;
			};
 
			flash@5809460 {
				device_type = "flash0";
				compatible = "allwinner,sunxi-flash";
				reg = <0x00 0x5809460 0x00 0x10>;
				flash0_type = <0x02>;
				flash0_en;
				flash0_mode;
				flash0_flvdd = [00];
				flash0_flvdd_vol;
				device_id = <0x00>;
				status = "disabled";
				phandle = <0x66>;
			};
 
			sensor@5809470 {
				reg = <0x00 0x5809470 0x00 0x10>;
				device_type = "sensor0";
				compatible = "allwinner,sunxi-sensor";
				sensor0_mname = "ov5640";
				sensor0_twi_cci_id = <0x02>;
				sensor0_twi_addr = <0x78>;
				sensor0_mclk_id = <0x00>;
				sensor0_pos = "rear";
				sensor0_isp_used = <0x00>;
				sensor0_fmt = <0x00>;
				sensor0_stby_mode = <0x00>;
				sensor0_vflip = <0x00>;
				sensor0_hflip = <0x00>;
				sensor0_iovdd-supply;
				sensor0_iovdd_vol;
				sensor0_avdd-supply;
				sensor0_avdd_vol;
				sensor0_dvdd-supply;
				sensor0_dvdd_vol;
				sensor0_power_en;
				sensor0_reset = <0x1d 0x04 0x09 0x01>;
				sensor0_pwdn = <0x1d 0x04 0x08 0x01>;
				sensor0_sm_vs;
				flash_handle = <0x66>;
				act_handle = <0x67>;
				device_id = <0x00>;
				status = "okay";
			};
 
			sensor@5809480 {
				reg = <0x00 0x5809480 0x00 0x10>;
				device_type = "sensor1";
				compatible = "allwinner,sunxi-sensor";
				sensor1_mname = "ov5647";
				sensor1_twi_cci_id = <0x03>;
				sensor1_twi_addr = <0x6c>;
				sensor1_mclk_id = <0x01>;
				sensor1_pos = "front";
				sensor1_isp_used = <0x00>;
				sensor1_fmt = <0x00>;
				sensor1_stby_mode = <0x00>;
				sensor1_vflip = <0x00>;
				sensor1_hflip = <0x00>;
				sensor1_iovdd-supply;
				sensor1_iovdd_vol;
				sensor1_avdd-supply;
				sensor1_avdd_vol;
				sensor1_dvdd-supply;
				sensor1_dvdd_vol;
				sensor1_power_en;
				sensor1_reset = <0x1d 0x04 0x07 0x01>;
				sensor1_pwdn = <0x1d 0x04 0x06 0x01>;
				sensor1_sm_vs;
				flash_handle;
				act_handle;
				device_id = <0x01>;
				status = "okay";
			};
 
			vinc@5809000 {
				compatible = "allwinner,sunxi-vin-core";
				device_type = "vinc0";
				reg = <0x00 0x5809000 0x00 0x200>;
				interrupts-extended = <0x0a 0x6f 0x04>;
				vinc0_csi_sel = <0x00>;
				vinc0_mipi_sel = <0xff>;
				vinc0_isp_sel = <0x00>;
				vinc0_tdm_rx_sel = <0xff>;
				vinc0_rear_sensor_sel = <0x00>;
				vinc0_front_sensor_sel = <0x00>;
				vinc0_sensor_list = <0x00>;
				device_id = <0x00>;
				iommus = <0x1a 0x01 0x01>;
				status = "okay";
			};
 
			vinc@5809200 {
				device_type = "vinc1";
				compatible = "allwinner,sunxi-vin-core";
				reg = <0x00 0x5809200 0x00 0x200>;
				interrupts-extended = <0x0a 0x70 0x04>;
				vinc1_csi_sel = <0x00>;
				vinc1_mipi_sel = <0xff>;
				vinc1_isp_sel = <0x01>;
				vinc1_tdm_rx_sel = <0xff>;
				vinc1_rear_sensor_sel = <0x00>;
				vinc1_front_sensor_sel = <0x00>;
				vinc1_sensor_list = <0x00>;
				device_id = <0x01>;
				iommus = <0x1a 0x01 0x01>;
				status = "okay";
			};
		};
 
		tvd@05c00000 {
			compatible = "allwinner,sunxi-tvd";
			reg = <0x00 0x5c00000 0x00 0x10000>;
			interrupts-extended = <0x0a 0x7b 0x04>;
			clocks = <0x01 0x7c 0x01 0x35>;
			clock-names = "clk_bus_tvd_top\0clk_mbus_tvd";
			resets = <0x01 0x3c>;
			reset-names = "rst_bus_tvd_top";
			tvd-number = <0x01>;
			tvds = <0x68>;
			status = "okay";
			tvd_sw = <0x01>;
			tvd_interface = <0x00>;
			tvd_format = <0x00>;
			tvd_system = <0x01>;
			tvd_row = <0x01>;
			tvd_column = <0x01>;
			tvd_channel0_en = <0x01>;
			tvd_channel1_en = <0x00>;
			tvd_channel2_en = <0x00>;
			tvd_channel3_en = <0x00>;
		};
 
		tvd0@05c01000 {
			compatible = "allwinner,sunxi-tvd0";
			reg = <0x00 0x5c01000 0x00 0x10000>;
			interrupts-extended = <0x0a 0x7b 0x04>;
			clocks = <0x01 0x7a 0x01 0x7b>;
			clock-names = "clk_tvd0\0clk_bus_tvd0";
			resets = <0x01 0x3b>;
			reset-names = "rst_bus_tvd0";
			assigned-clocks = <0x01 0x7a>;
			assigned-clock-parents = <0x01 0x0b>;
			tvd_used = <0x01>;
			tvd_if = <0x00>;
			status = "okay";
			used = <0x01>;
			agc_auto_enable = <0x01>;
			agc_manual_value = <0x40>;
			cagc_enable = <0x01>;
			fliter_used = <0x01>;
			phandle = <0x68>;
		};
 
		card0_boot_para@2 {
			reg = <0x00 0x02 0x00 0x00>;
			device_type = "card0_boot_para";
			card_ctrl = <0x00>;
			card_high_speed = <0x01>;
			card_line = <0x04>;
			pinctrl-0 = <0x53>;
		};
 
		card2_boot_para@3 {
			reg = <0x00 0x03 0x00 0x00>;
			device_type = "card2_boot_para";
			card_ctrl = <0x02>;
			card_high_speed = <0x01>;
			card_line = <0x04>;
			pinctrl-0 = <0x51>;
			sdc_io_1v8 = <0x01>;
			sdc_tm4_hs200_max_freq = <0x96>;
			sdc_tm4_hs400_max_freq = <0x64>;
			sdc_ex_dly_used = <0x02>;
		};
 
		rfkill@0 {
			compatible = "allwinner,sunxi-rfkill";
			chip_en;
			power_en;
			status = "okay";
 
			wlan@0 {
				compatible = "allwinner,sunxi-wlan";
				wlan_busnum = <0x01>;
				wakeup-source;
			};
 
			bt@0 {
				compatible = "allwinner,sunxi-bt";
				bt_rst_n = <0x1d 0x06 0x12 0x01>;
				status = "okay";
			};
		};
 
		btlpm@0 {
			compatible = "allwinner,sunxi-btlpm";
			uart_index = <0x01>;
			bt_wake = <0x1d 0x06 0x10 0x00>;
			bt_hostwake = <0x1d 0x06 0x11 0x00>;
			status = "okay";
		};
 
		addr_mgt@0 {
			compatible = "allwinner,sunxi-addr_mgt";
			type_addr_wifi = <0x00>;
			type_addr_bt = <0x00>;
			type_addr_eth = <0x00>;
			status = "okay";
		};
 
		battery@0 {
			compatible = "simple-battery";
			constant-charge-current-max-microamp = <0x200b20>;
			voltage-min-design-microvolt = <0x325aa0>;
			phandle = <0x28>;
		};
 
		wifi-pwrseq {
			compatible = "mmc-pwrseq-simple";
			clocks = <0x69 0x01>;
			clock-names = "ext_clock";
			reset-gpios = <0x1d 0x06 0x0b 0x01>;
			post-power-on-delay-ms = <0xc8>;
			phandle = <0x5c>;
		};
	};
 
	dsp0 {
		compatible = "allwinner,sun20iw1-dsp";
		status = "okay";
	};
 
	dsp0_gpio_int {
		compatible = "allwinner,sun20iw1-dsp-gpio-int";
		pin-group = "PB\0PC\0PD\0PE";
		status = "disabled";
	};
 
	vdd-cpu {
		compatible = "sunxi-pwm-regulator";
		pwms = <0x6a 0x00 0x1388 0x01>;
		regulator-name = "vdd_cpu";
		regulator-min-microvolt = <0xc5c10>;
		regulator-max-microvolt = <0x11b340>;
		regulator-ramp-delay = <0x19>;
		regulator-always-on;
		regulator-boot-on;
		status = "okay";
		phandle = <0x04>;
	};
 
	usb1-vbus {
		compatible = "regulator-fixed";
		regulator-name = "usb1-vbus";
		regulator-min-microvolt = <0x4c4b40>;
		regulator-max-microvolt = <0x4c4b40>;
		regulator-enable-ramp-delay = <0x3e8>;
		enable-active-high;
		phandle = <0x5d>;
	};
 
	backlight@0 {
		compatible = "ocp8178-backlight";
		backlight-control-gpios = <0x1d 0x03 0x14 0x00>;
		default-brightness = <0x05>;
	};
};
